# CW32L012 register map
Vendor: Wuhan Xinyuan Semiconductor Co.Ltd; Series: ARMCM0P; File version: 1.2
CPU: CM0+ r0p1, little endian, no MPU, no FPU, VTOR, 2 interrupt priority bits
Registers are 32-bit, read-write, no defined reset value unless marked. A register's access mark holds for its fields unless they carry their own. Offsets are from the block's base; [hi:lo] are bit positions; {n}, {i} and the like mark numbered series; 'fields as' and 'values as' point back to an identical list.

## EAU
Base 0x40023200
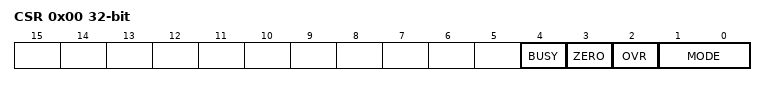
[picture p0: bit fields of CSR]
0x00 CSR
  [4] BUSY ro, [3] ZERO ro, [2] OVR ro, [1:0] MODE
0x04 DIVIDEND
0x08 DIVISOR
0x0C QUOTIENT ro
0x10 REMAINDER ro

## FLASH
Base 0x40022000
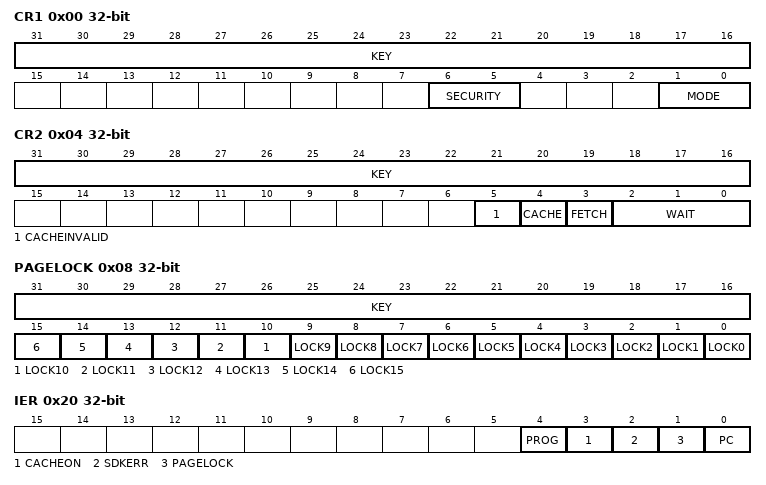
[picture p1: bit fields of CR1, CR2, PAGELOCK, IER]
0x00 CR1 — Control register1
  [31:16] KEY wo, [6:5] SECURITY ro, [1:0] MODE
0x04 CR2 — Control register2
  [31:16] KEY wo, [5] CACHEINVALID, [4] CACHE, [3] FETCH, [2:0] WAIT
0x08 PAGELOCK — Page Write Erase Lock
  [31:16] KEY wo
  [n] LOCK{n} (n=0..15) — Page{8n} - {8n+7}
0x20 IER — Interrupt enable register
  [4] PROG, [3] CACHEON, [2] SDKERR, [1] PAGELOCK, [0] PC
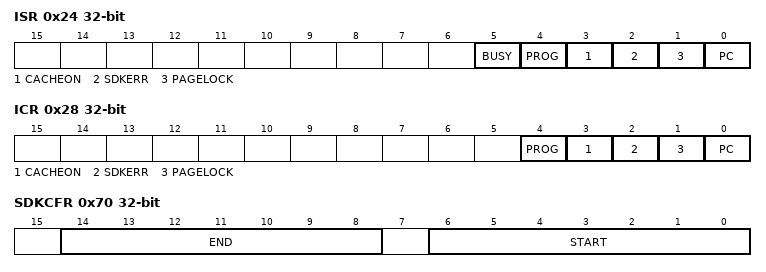
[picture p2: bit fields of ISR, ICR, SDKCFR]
0x24 ISR ro — Interrupt status register
  [5] BUSY, [4] PROG, [3] CACHEON, [2] SDKERR, [1] PAGELOCK, [0] PC
0x28 ICR — Interrupt flag clear register
  [4] PROG, [3] CACHEON, [2] SDKERR, [1] PAGELOCK, [0] PC
0x70 SDKCFR ro — SDK config register
  [14:8] END, [6:0] START

## GPIOA
Base 0x48000000
Same registers: GPIOB 0x48000100, GPIOC 0x48000200, GPIOF 0x48000300
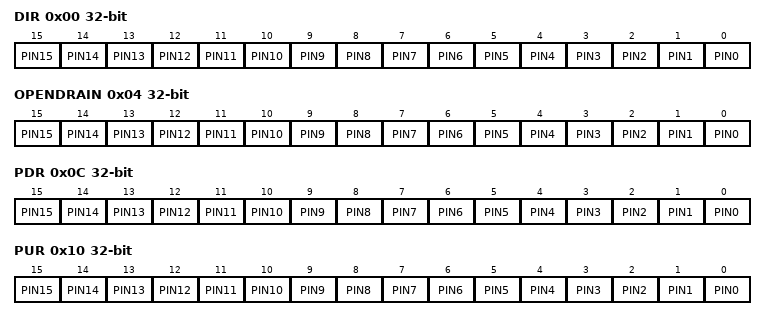
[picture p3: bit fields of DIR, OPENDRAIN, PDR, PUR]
0x00 DIR
  [n] PIN{n} (n=0..15)
0x04 OPENDRAIN
  [n] PIN{n} (n=0..15)
0x0C PDR — GPIO PDR
  [n] PIN{n} (n=0..15)
0x10 PUR
  [n] PIN{n} (n=0..15)
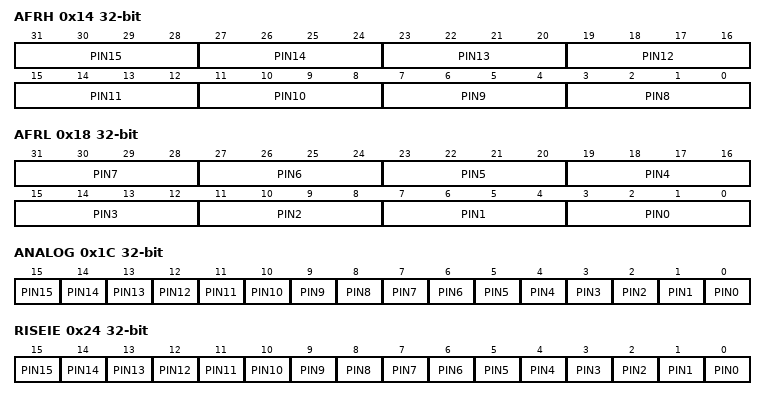
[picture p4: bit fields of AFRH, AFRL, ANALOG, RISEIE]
0x14 AFRH
  [4n-29:4n-32] PIN{n} (n=8..15) — desc AFR{n}
0x18 AFRL
  [4n+3:4n] PIN{n} (n=0..7) — desc AFR{n}
0x1C ANALOG
  [n] PIN{n} (n=0..15)
0x24 RISEIE — Interrupt enable register
  [n] PIN{n} (n=0..15)
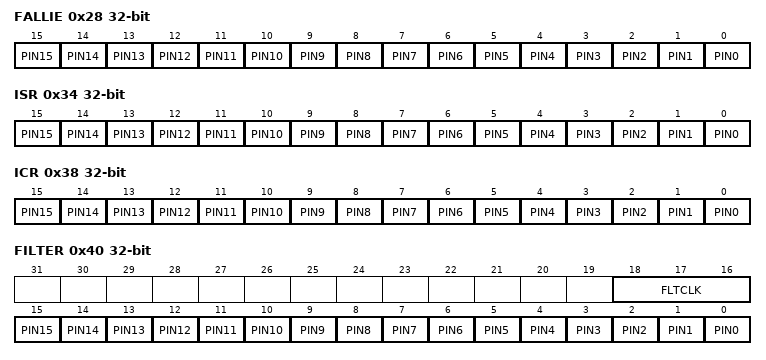
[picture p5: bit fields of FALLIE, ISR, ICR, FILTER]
0x28 FALLIE — Interrupt enable register
  [n] PIN{n} (n=0..15)
0x34 ISR ro — Interrupt status register
  [n] PIN{n} (n=0..15)
0x38 ICR — Interrupt flag clear register
  [n] PIN{n} (n=0..15)
0x40 FILTER
  [18:16] FLTCLK, [n] PIN{n} (n=0..15)
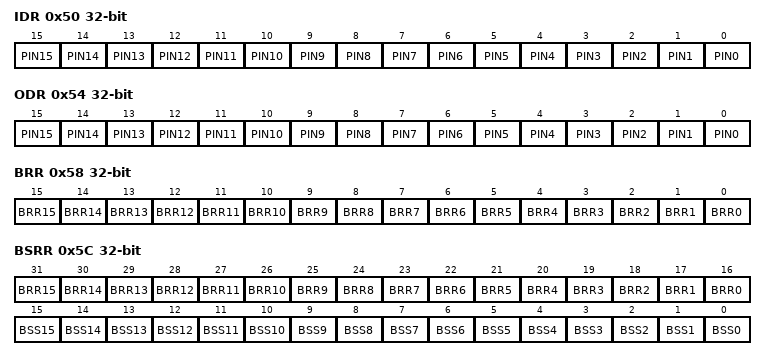
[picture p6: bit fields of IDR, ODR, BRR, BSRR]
0x50 IDR ro
  [n] PIN{n} (n=0..15)
0x54 ODR
  [n] PIN{n} (n=0..15)
0x58 BRR
  [n] BRR{n} (n=0..15)
0x5C BSRR
  [n+16] BRR{n} (n=0..15), [n] BSS{n} (n=0..15)
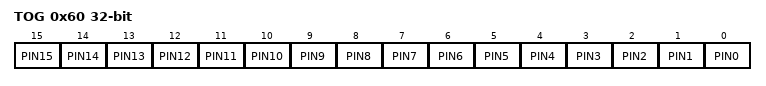
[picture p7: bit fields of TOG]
0x60 TOG
  [n] PIN{n} (n=0..15)

## GTIM1 — General Timer 1
Base 0x40001800
Same registers: GTIM2 0x40001C00, GTIM3 0x40002400, GTIM4 0x40002800
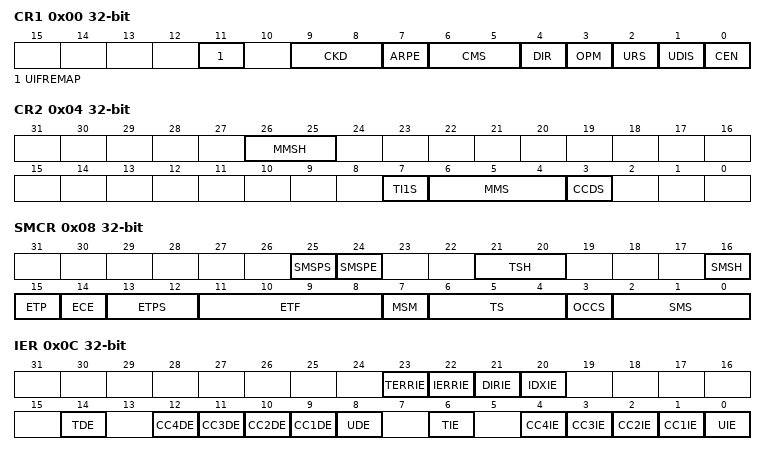
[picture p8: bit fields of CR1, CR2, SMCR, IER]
0x00 CR1 — Control register1
  [11] UIFREMAP, [9:8] CKD, [7] ARPE, [6:5] CMS, [4] DIR, [3] OPM, [2] URS, [1] UDIS, [0] CEN
0x04 CR2 — Control register2
  [26:25] MMSH, [7] TI1S, [6:4] MMS, [3] CCDS
0x08 SMCR — Slave Mode control register
  [25] SMSPS, [24] SMSPE, [21:20] TSH, [16] SMSH, [15] ETP, [14] ECE, [13:12] ETPS, [11:8] ETF, [7] MSM, [6:4] TS, [3] OCCS, [2:0] SMS
0x0C IER — Interrupt control register
  [23] TERRIE, [22] IERRIE, [21] DIRIE, [20] IDXIE, [14] TDE, [n+8] CC{n}DE (n=1..4), [8] UDE, [6] TIE, [n] CC{n}IE (n=1..4), [0] UIE
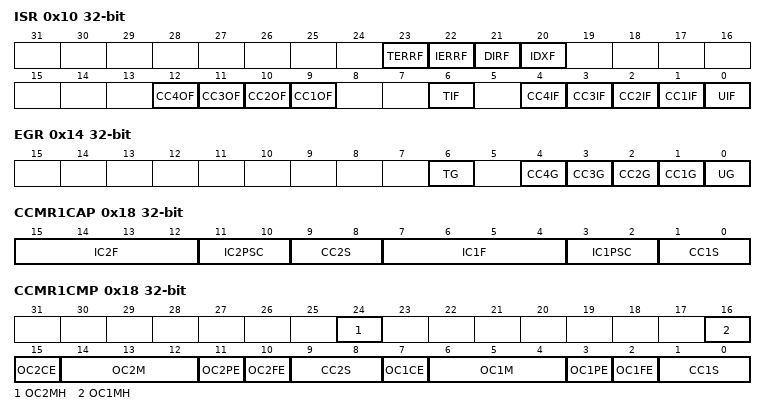
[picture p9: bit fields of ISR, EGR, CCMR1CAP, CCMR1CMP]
0x10 ISR ro — Interrupt status register
  [23] TERRF, [22] IERRF, [21] DIRF, [20] IDXF, [n+8] CC{n}OF (n=1..4), [6] TIF, [n] CC{n}IF (n=1..4), [0] UIF
0x14 EGR — Event Generate register
  [6] TG, [n] CC{n}G (n=1..4), [0] UG
0x18 CCMR1CAP — Capture control Register1
  [15:12] IC2F, [11:10] IC2PSC, [9:8] CC2S, [7:4] IC1F, [3:2] IC1PSC, [1:0] CC1S
0x18 CCMR1CMP (alternate view of CCMR1CAP) — Compare control Register1
  [24] OC2MH, [16] OC1MH, [15] OC2CE, [14:12] OC2M, [11] OC2PE, [10] OC2FE, [9:8] CC2S, [7] OC1CE, [6:4] OC1M, [3] OC1PE, [2] OC1FE, [1:0] CC1S
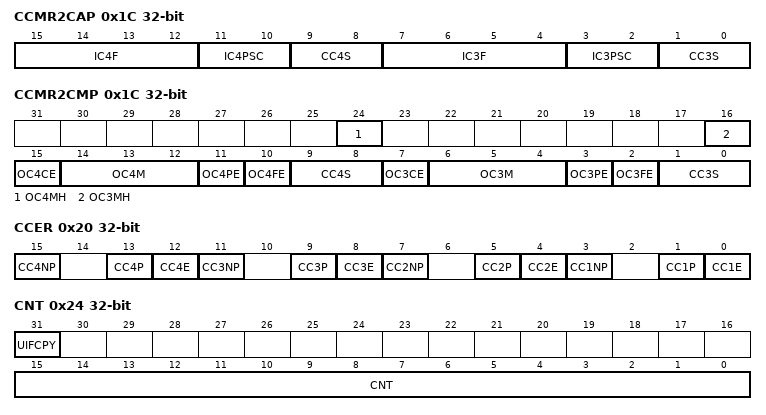
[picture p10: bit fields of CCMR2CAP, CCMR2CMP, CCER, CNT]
0x1C CCMR2CAP — Capture control Register2
  [15:12] IC4F, [11:10] IC4PSC, [9:8] CC4S, [7:4] IC3F, [3:2] IC3PSC, [1:0] CC3S
0x1C CCMR2CMP (alternate view of CCMR2CAP) — Compare control Register2
  [24] OC4MH, [16] OC3MH, [15] OC4CE, [14:12] OC4M, [11] OC4PE, [10] OC4FE, [9:8] CC4S, [7] OC3CE, [6:4] OC3M, [3] OC3PE, [2] OC3FE, [1:0] CC3S
0x20 CCER — Capture compare Enable Register
  [4n-1] CC{n}NP (n=1..4), [4n-3] CC{n}P (n=1..4), [4n-4] CC{n}E (n=1..4)
0x24 CNT — Counter Register
  [31] UIFCPY ro, [15:0] CNT
0x28 PSC — Prescaler Control Register
  [15:0] PSC
0x2C ARR — Auto Reload Register
  [15:0] ARR
{0x30+4i} CCR{i} (i=1..4) — Capture control Register{i}
  [15:0] CCR{i}
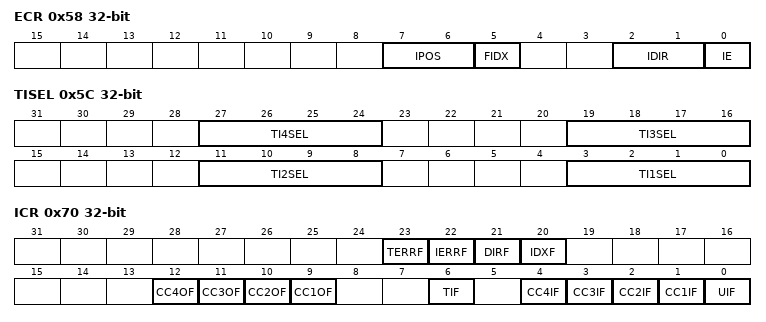
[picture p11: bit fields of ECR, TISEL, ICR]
0x58 ECR — Encoder control Register
  [7:6] IPOS, [5] FIDX, [2:1] IDIR, [0] IE
0x5C TISEL — Timer Input Select Register
  [8n-5:8n-8] TI{n}SEL (n=1..4)
0x60 AF1 — Alternate function Register1
  [17:14] ETRSEL
0x64 AF2 — Alternate function Register2
  [18:16] OCRSEL
0x70 ICR — Interrupt flag clear register
  fields as ISR
